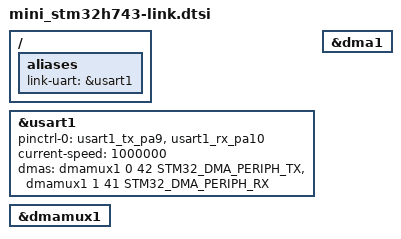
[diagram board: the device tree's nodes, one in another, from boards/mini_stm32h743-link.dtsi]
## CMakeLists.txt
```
cmake_minimum_required(VERSION 3.20.0)

# Which end of the wire this build is:
#   -DLINK_ROLE=initiator   the F767, which measures
#   -DLINK_ROLE=responder   the H743, which echoes
set(LINK_ROLE "initiator" CACHE STRING "initiator or responder")

# Link speed, in baud. Both ends must match. 1/2/3/4/6 Mbaud are exact on both
# boards; above 6 needs 8x oversampling and will not survive jumper wires.
set(LINK_BAUD "1000000" CACHE STRING "link UART baud rate")

# Which application this is:
#   -DLINK_MODE=dma      stage E3 - DMA both ways, interrupts enabled (default)
#   -DLINK_MODE=polled   stage E2 - the polled probe, kept runnable
#
# E2 is not dead code. Its numbers are what E3 is measured against, and a
# comparison made on the same boards on the same day is worth more than one
# made against a README. It is also the only build here that still proves the
# wire itself, with nothing between it and the peripheral.
set(LINK_MODE "dma" CACHE STRING "dma (E3) or polled (E2)")

if(BOARD STREQUAL "nucleo_f767zi")
  set(LINK_UART "usart6")
elseif(BOARD STREQUAL "mini_stm32h743")
  set(LINK_UART "usart1")
else()
  message(FATAL_ERROR "link: no link UART known for board '${BOARD}'")
endif()

configure_file(link-baud.overlay.in ${CMAKE_CURRENT_BINARY_DIR}/link-baud.overlay @ONLY)
list(APPEND EXTRA_DTC_OVERLAY_FILE ${CMAKE_CURRENT_BINARY_DIR}/link-baud.overlay)

find_package(Zephyr REQUIRED HINTS $ENV{ZEPHYR_BASE})
project(ctrl_lab_link)

if(LINK_ROLE STREQUAL "initiator")
  target_compile_definitions(app PRIVATE LINK_INITIATOR=1)
elseif(LINK_ROLE STREQUAL "responder")
  target_compile_definitions(app PRIVATE LINK_RESPONDER=1)
else()
  message(FATAL_ERROR "link: LINK_ROLE must be initiator or responder")
endif()

message(STATUS "link: ${BOARD} as ${LINK_ROLE}, ${LINK_UART} at ${LINK_BAUD} baud, mode ${LINK_MODE}")

target_include_directories(app PRIVATE src ../ctrl/src)

if(LINK_MODE STREQUAL "dma")
  target_sources(app PRIVATE src/e3_link.c src/link_dma.c src/link_frame.c
                             src/link_latch.c ../ctrl/src/dcp.c)
elseif(LINK_MODE STREQUAL "polled")
  target_sources(app PRIVATE src/main.c ../ctrl/src/dcp.c ../ctrl/src/trace.c)
else()
  message(FATAL_ERROR "link: LINK_MODE must be dma or polled")
endif()

# Same reason as firmware/ctrl: never let the compiler contract a*b+c into an
# FMA. Nothing here is float-heavy, but the CRC and framing code is shared with
# the control core and the two must stay byte-identical.
target_compile_options(app PRIVATE -ffp-contract=off -fno-fast-math)
```

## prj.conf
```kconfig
# The link receives by DMA, not by polling.
#
# E2 measured the polled path to its limit. uart_poll_in has to be called again
# before the next byte lands - 1.7 us at 6 Mbaud - and the 10 kHz kernel tick
# ISR is longer than that, so the poll loop lost one to three bytes per frame,
# sporadically. irq_lock() around the whole frame made it deterministic, and
# that is precisely what E3 cannot do: a control loop cannot go deaf for 40 ms,
# and locking interrupts would suppress the jitter this stage exists to
# measure. See bead ctrl-lab-b7r.7 for the decision and the alternatives.
#
# The async API moves the deadline off the CPU entirely: the DMA controller
# writes bytes into RAM on its own and the driver only wakes at buffer
# boundaries, so a late thread costs latency instead of data.
CONFIG_SERIAL=y
CONFIG_UART_ASYNC_API=y

# UART_ASYNC_API already selects DMA (drivers/serial/Kconfig.stm32:18), but the
# DMA controllers still have to be enabled per board in the overlays. Stating
# it here as well means a build that somehow loses an overlay fails on a
# missing controller rather than quietly falling back to something slower.
CONFIG_DMA=y

# The DMA ring must not be cached. Both parts are Cortex-M7 with D-cache on by
# default, and the STM32 async UART driver does no cache maintenance of its
# own - upstream's own async_api sample works around this by setting
# CONFIG_DCACHE=n on both nucleo_f746zg and nucleo_h753zi.
#
# Switching the cache off is the wrong trade here: firmware/ctrl/README.md
# measured what it buys on the H743, and E3 wants that. So instead the ring
# goes in the MPU-backed nocache section and the rest of RAM stays cacheable.
CONFIG_ARM_MPU=y
CONFIG_NOCACHE_MEMORY=y

# Cycle-accurate timing, same DWT-backed API the control runtime uses.
CONFIG_TIMING_FUNCTIONS=y

CONFIG_MAIN_STACK_SIZE=4096
```

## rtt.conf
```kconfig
# Console over RTT, for the H743 responder. Identical to firmware/ctrl/rtt.conf
# and for the same three reasons; see firmware/BRINGUP.md.
CONFIG_USE_SEGGER_RTT=y
CONFIG_RTT_CONSOLE=y
CONFIG_UART_CONSOLE=n
CONFIG_SEGGER_RTT_SECTION_DTCM=y
CONFIG_SEGGER_RTT_BUFFER_SIZE_UP=8192
```

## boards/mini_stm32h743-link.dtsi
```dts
/*
 * The link end of the H743, shared by every application that talks over it.
 * See the F767 companion for why this is included rather than duplicated.
 */

/*
 * The link end of the H743: usart1 on PA9/PA10, which the board leaves free.
 *
 *   PA9  = USART1_TX  ->  F767 D0 (PG9, RX)
 *   PA10 = USART1_RX  <-  F767 D1 (PG14, TX)
 *   GND <-> GND
 *
 * usart1 is on APB2 at 120 MHz, the fastest peripheral bus here. PB6/PB7 would
 * also carry usart1 but PB6 is QuadSPI NCS for the onboard NOR flash; PB14/PB15
 * are the clean alternative if PA9 ever turns out to be tied to USB VBUS on a
 * given board revision.
 *
 * gcd(108, 120) = 12, so 1/2/3/4/6 Mbaud are exact on both ends with zero baud
 * error. See firmware/link/README.md.
 */

/ {
	aliases {
		link-uart = &usart1;
	};

};

&usart1 {
	pinctrl-0 = <&usart1_tx_pa9 &usart1_rx_pa10>;
	pinctrl-names = "default";
	current-speed = <1000000>;
	status = "okay";

	/*
	 * DMA for the link. The H7 routes requests through DMAMUX rather than
	 * hardwiring them to streams, so the numbers mean something different
	 * than on the F767: the first cell is a DMAMUX channel (free choice)
	 * and the second is the request line ID (fixed by the peripheral).
	 * RM0433 table 121: usart1_rx_dma is 41 and usart1_tx_dma is 42.
	 *
	 * DMAMUX1 channels 0-7 are DMA1 streams 0-7 and 8-15 are DMA2's, so
	 * channels 0 and 1 put both directions on DMA1 and leave DMA2 off.
	 */
	dmas = <&dmamux1 0 42 STM32_DMA_PERIPH_TX>,
	       <&dmamux1 1 41 STM32_DMA_PERIPH_RX>;
	dma-names = "tx", "rx";
};

/*
 * DMA1 only: nothing else here needs a stream, and dmamux_stm32 resolves the
 * channel-to-controller table at build time, so a disabled DMA2 costs nothing
 * beyond the channels that would have mapped to it.
 *
 * The ring these streams write into must stay out of DTCM. DMA1 lives in the
 * D2 domain and cannot reach the D1 core-coupled memories at all; sram0 on
 * this board is AXI SRAM at 0x24000000, which it reaches through the D2-to-D1
 * bus matrix. That is the opposite of the rule for the control pools in
 * firmware/BRINGUP.md, and the reason link buffers must not follow them into
 * dtcm.
 */
&dma1 {
	status = "okay";
};

&dmamux1 {
	status = "okay";
};
```

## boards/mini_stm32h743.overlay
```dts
/* The link probe's own overlay. The link itself is in the shared .dtsi, which
 * firmware/ctrl includes too; the DTCM selection stays here because it is a
 * per-application choice.
 */

#include "mini_stm32h743-link.dtsi"

/ {
	chosen {
		/* Same reason as every other application here: the board .dts
		 * declares dtcm but never selects it, so without this the
		 * __dtcm_* sections do not exist. See firmware/BRINGUP.md.
		 */
		zephyr,dtcm = &dtcm;
	};
};
```

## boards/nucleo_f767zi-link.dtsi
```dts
/*
 * The link end of the F767, shared by every application that talks over it.
 *
 * Included rather than duplicated: firmware/ctrl needs exactly these nodes to
 * bind an Input or Output block to the link, and a second copy of the DMA
 * stream numbers is a second place to get them wrong. The DTCM selection in
 * each app's own overlay stays duplicated, because that is one line of settled
 * board fact; this is not.
 */

/*
 * The link end of the F767: usart6, which is the Arduino header's serial.
 *
 *   D1 = PG14 = USART6_TX  ->  H743 PA10 (RX)
 *   D0 = PG9  = USART6_RX  <-  H743 PA9  (TX)
 *   GND <-> GND
 *
 * usart6 is on APB2 at 108 MHz, twice the clock of the APB1 UARTs, which is why
 * it is the link rather than a spare usart2. It is already enabled in the board
 * .dts at 115200; the generated link-baud.overlay overrides the speed.
 *
 * The console stays on usart3 (ST-Link VCP), so measurements print over a
 * channel that is not the one being measured.
 */

/ {
	aliases {
		link-uart = &usart6;
	};
};

/*
 * DMA for the link UART. RM0410 table 28: DMA2 channel 5 carries USART6_TX on
 * streams 6 and 7, and USART6_RX on streams 1 and 2. Nothing else in this
 * application uses DMA2, so the first of each pair is free.
 *
 * The fourth cell is the FIFO threshold. It is inert here - dma_stm32 only
 * turns the stream FIFO on when a burst is configured (stm32_dma_configure ->
 * stm32_dma_check_fifo_mburst) and the async UART driver transfers single
 * bytes, so the stream runs in direct mode. It is spelled out anyway because
 * the binding requires four cells and because this is what upstream's own
 * async_api sample passes on the F7.
 */
&usart6 {
	dmas = <&dma2 6 5 STM32_DMA_PERIPH_TX STM32_DMA_FIFO_FULL>,
	       <&dma2 1 5 STM32_DMA_PERIPH_RX STM32_DMA_FIFO_FULL>;
	dma-names = "tx", "rx";
};

&dma2 {
	status = "okay";
};
```

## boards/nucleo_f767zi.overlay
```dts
/* The link probe's own overlay. The link itself is in the shared .dtsi, which
 * firmware/ctrl includes too.
 */

#include "nucleo_f767zi-link.dtsi"
```

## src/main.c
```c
/*
 * ctrl-lab link probe - stage E2.
 *
 * Moves bytes between the two boards and finds out what they cost. No control
 * loop, no plan execution: the only unknown this stage adds is the transport,
 * and mixing it with anything else would make a bad number unattributable.
 *
 *   F767 (initiator)  D1 = PG14 = usart6 TX  ->  PA10 = usart1 RX  (H743)
 *                     D0 = PG9  = usart6 RX  <-  PA9  = usart1 TX
 *                     GND <-> GND
 *
 * Both link UARTs are on APB2 - 108 MHz on the F767, 120 MHz on the H743 -
 * which is the fastest peripheral clock on each part.
 *
 * Two measurements:
 *
 *   ping   one byte out, one byte back, timed on the initiator's clock. This is
 *          the only way to get an accurate delay across two boards that have no
 *          shared timebase: measure the round trip on one clock, and have the
 *          far side report its own turnaround so it can be subtracted.
 *
 *   frame  a real DCPT frame, verified on the far side with the same CRC code
 *          the control runtime uses. Answers whether the link is trustworthy
 *          for stage E3, and what it costs in throughput.
 *
 * What `ping` does NOT measure: uart_poll_out returns once the byte is handed
 * to the transmit register, not once it has left the wire. The last character
 * time is therefore outside the measurement on each hop. At 1 Mbaud that is
 * 10 us per direction, which is large - so the reported delay is a lower bound
 * on the wire time and an accurate measure of software-to-software latency.
 */

#include <zephyr/kernel.h>
#include <zephyr/device.h>
#include <zephyr/drivers/uart.h>
#include <zephyr/sys/printk.h>
#include <string.h>
#include <zephyr/timing/timing.h>

#include "dcp.h"
#include "trace.h"

#define LINK_NODE DT_ALIAS(link_uart)
#if !DT_NODE_EXISTS(LINK_NODE)
#error "no link-uart alias - add one in boards/<board>.overlay"
#endif

static const struct device *const link = DEVICE_DT_GET(LINK_NODE);

/* Protocol, deliberately one byte wide. Anything richer would need framing of
 * its own, and the DCPT frame already brings framing for the payload.
 */
#define CMD_PING  'P'
#define RSP_PING  'p'
#define CMD_FRAME 'F'
#define CMD_REPORT 'R'
#define RSP_CRC_OK   'Y'
#define RSP_CRC_BAD  'N'

#define PING_COUNT 1000

/* A synthetic trace frame: 200 rows of 4 signals. Big enough that throughput
 * means something, small enough to sit in RAM on both boards.
 */
#define FRAME_ROWS    200
#define FRAME_SIGNALS 4
#define FRAME_BYTES (CTRL_TRACE_HEADER_LEN + \
		     FRAME_ROWS * (1 + FRAME_SIGNALS) * 4 + CTRL_TRACE_TRAILER_LEN)

static uint8_t frame[FRAME_BYTES];

/* Blocking single-byte read. Returns false if nothing arrived within the
 * timeout, which is what distinguishes "the far side is not there" from "the
 * far side is slow".
 */
/* Bulk receive with an absolute deadline.
 *
 * The fast path does NO timing work at all: while bytes keep arriving,
 * uart_poll_in succeeds and nothing else is called. The deadline is only
 * consulted when a poll comes back empty, which is the only time the answer can
 * have changed.
 *
 * That matters more than it looks. The first version called link_get() once per
 * byte, and each call read sys_clock_hw_cycles_per_sec() and k_cycle_get_32()
 * to build a fresh deadline. At 1 Mbaud a byte lands every 10 us and that fits;
 * at 2 Mbaud the budget halves to 5 us and it does not, so the receiver fell
 * behind a blast it could easily keep up with and every frame above 1 Mbaud
 * failed CRC while single-byte pings at 6 Mbaud were flawless. Measured.
 */
#ifdef LINK_RESPONDER
static uint32_t cycles_per_ms;

/* Bulk receive that does NO timing work until a byte is actually late.
 *
 * Every boundary in this protocol turned out to be a place where a few hundred
 * cycles of bookkeeping loses a byte, because the STM32 receive register holds
 * exactly one and the sender never pauses. It cost four rounds to learn:
 *
 *   - a bitwise CRC between payload and trailer lost 11 of 12 trailer bytes
 *   - a 24-byte header CRC before the payload lost 1
 *   - and building a deadline (which called sys_clock_hw_cycles_per_sec) after
 *     reading the 'F' command lost the first header byte, which shifted the
 *     whole frame by one and showed up as "header 32/32 (crc bad),
 *     trailer 11/12"
 *
 * So the deadline is armed lazily: nothing is computed while bytes are
 * arriving, and the clock is only read once a poll comes back empty. The fast
 * path is uart_poll_in and nothing else.
 */
static uint32_t link_recv(uint8_t *out, uint32_t len, uint32_t timeout_ms)
{
	uint32_t got = 0;
	uint32_t deadline = 0;
	bool armed = false;

	while (got < len) {
		if (uart_poll_in(link, &out[got]) == 0) {
			got++;
			armed = false;
			continue;
		}
		if (!armed) {
			deadline = k_cycle_get_32() + timeout_ms * cycles_per_ms;
			armed = true;
			continue;
		}
		if ((int32_t)(k_cycle_get_32() - deadline) >= 0) {
			break;
		}
	}
	return got;
}
#endif /* LINK_RESPONDER */

#ifdef LINK_INITIATOR
static bool link_get(uint8_t *out, uint32_t timeout_us)
{
	/* Spin tightly. The first version slept k_busy_wait(1) between polls,
	 * which reads the cycle counter and costs far more than the 1 us it
	 * claims - at 1 Mbaud a byte lands every 10 us and the STM32 USART
	 * receive register holds exactly one, so a slow poll loop overruns it and
	 * drops bytes. That showed up as a frame CRC mismatch and a transfer
	 * running 5x slower than the wire, because every dropped byte then cost a
	 * full receive timeout. Measured, not theorised: 4044 bytes took 210 ms
	 * against a 40 ms floor.
	 *
	 * The deadline is compared as a signed difference so the 32-bit cycle
	 * counter wrapping mid-wait is harmless.
	 */
	const uint32_t per_us = sys_clock_hw_cycles_per_sec() / 1000000U;
	const uint32_t deadline = k_cycle_get_32() + timeout_us * per_us;

	do {
		if (uart_poll_in(link, out) == 0) {
			return true;
		}
	} while ((int32_t)(k_cycle_get_32() - deadline) < 0);

	return false;
}
#endif /* LINK_INITIATOR */

#ifdef LINK_INITIATOR
static void link_put(const uint8_t *bytes, uint32_t len)
{
	for (uint32_t i = 0; i < len; i++) {
		uart_poll_out(link, bytes[i]);
	}
}
#endif

/* --- frame construction, initiator only ---------------------------------- */

#ifdef LINK_INITIATOR
static uint32_t frame_len;

static void frame_sink(void *ctx, const uint8_t *bytes, uint32_t len)
{
	ARG_UNUSED(ctx);

	for (uint32_t i = 0; i < len && frame_len < sizeof(frame); i++) {
		frame[frame_len++] = bytes[i];
	}
}

/* Deterministic contents, so both ends can build the identical frame and any
 * disagreement is the wire rather than the data.
 */
static void build_frame(void)
{
	struct ctrl_trace_writer writer;
	float row[FRAME_SIGNALS];

	frame_len = 0;
	ctrl_trace_begin(&writer, frame_sink, NULL, 0x1234567890abcdefULL,
			 FRAME_SIGNALS, FRAME_ROWS);

	for (uint32_t k = 0; k < FRAME_ROWS; k++) {
		for (int s = 0; s < FRAME_SIGNALS; s++) {
			row[s] = (float)(k * FRAME_SIGNALS + s);
		}
		ctrl_trace_row(&writer, (float)k * 0.001f, row);
	}
	ctrl_trace_end(&writer);
}
#endif /* LINK_INITIATOR */

#ifdef LINK_RESPONDER

/* The H743 end. Never returns: it has to keep answering, and on this part
 * letting Zephyr idle into WFI also takes the core off the SWD debug bus, which
 * is how RTT is read. See firmware/BRINGUP.md.
 */
int main(void)
{
	printk("\nctrl-lab link responder\n");
	printk("board " CONFIG_BOARD_TARGET ", link %s\n", link->name);

	if (!device_is_ready(link)) {
		printk("FAIL: link uart not ready\n");
		return 0;
	}

	timing_init();
	timing_start();

	/* Hoisted: reading this per call was itself enough to drop a byte. */
	cycles_per_ms = sys_clock_hw_cycles_per_sec() / 1000U;

	uint32_t pings = 0, frames = 0, bad = 0, last_payload = 0;

	/* Where the last frame got to. Reported verbatim so a stall is located
	 * rather than inferred: which phase, and how many bytes of what it
	 * expected actually arrived.
	 */
	const char *phase = "none";
	uint32_t hdr_got = 0, pay_got = 0, trl_got = 0, stray = 0;
	bool hdr_crc_ok = false;
	uint32_t turn_best = UINT32_MAX, turn_worst = 0;
	uint64_t turn_total = 0;

	printk("listening\n");

	while (1) {
		uint8_t cmd;

		if (uart_poll_in(link, &cmd) != 0) {
			continue;
		}

		if (cmd != CMD_PING && cmd != CMD_FRAME && cmd != CMD_REPORT) {
			stray++;
			continue;
		}

		if (cmd == CMD_PING) {
			timing_t t0 = timing_counter_get();

			uart_poll_out(link, RSP_PING);

			timing_t t1 = timing_counter_get();
			uint32_t turn = (uint32_t)timing_cycles_get(&t0, &t1);

			turn_best = MIN(turn_best, turn);
			turn_worst = MAX(turn_worst, turn);
			turn_total += turn;
			pings++;

			/* Deliberately silent here. printk between the ping phase
			 * and the frame is enough to miss the first bytes of the
			 * frame: the STM32 USART holds one received byte and the
			 * initiator starts sending immediately. That cost a full
			 * baud sweep of CRC mismatches at every rate, including one
			 * that had passed minutes earlier. Stats are printed after
			 * the frame instead, when the link is quiet.
			 */
		} else if (cmd == CMD_FRAME) {
			/* Header first, because payload_len lives in it and must
			 * be CRC-checked before it is trusted as a length.
			 */
			uint8_t header[CTRL_TRACE_HEADER_LEN];

			/* 200 ms, deliberately SHORTER than the initiator's wait
			 * for our verdict.
			 *
			 * This is the bug that outlasted four fixes. The responder
			 * used to wait 2000 ms for missing bytes while the
			 * initiator gave up after 500 ms - so a single lost byte
			 * desynchronised them permanently: the initiator moved on
			 * and started the next phase while this side was still
			 * blocked, and every subsequent run inherited the mess.
			 * Whoever waits longer must be the one asking.
			 */
			/* Resynchronise on the magic instead of trusting stream
			 * position.
			 *
			 * The frame carries "DCPT" precisely so a reader can find it
			 * in a stream it does not otherwise understand, and not using
			 * that made every failure self-perpetuating: a frame that
			 * ended one byte short left a byte behind, the next run read
			 * it as the start of its header, and the shift repeated for
			 * ever. Failures went from intermittent to permanent and it
			 * looked like a rate problem.
			 *
			 * Scanning costs nothing in the good case - the magic is the
			 * first four bytes - and it makes a bad frame cost exactly
			 * one frame instead of every frame after it.
			 */
			/* Interrupts off for the whole frame.
			 *
			 * The instrumentation narrowed the loss to mid-stream and
			 * sporadic - trailer short by one to three bytes, varying
			 * run to run - which a tight poll loop cannot cause on its
			 * own at 10 us per byte. What can is the 10 kHz kernel tick
			 * preempting it: the H743's ISR path is both expensive and
			 * variable, which the E1 jitter work already measured
			 * (5183 ns of tick jitter, and awake-time outliers).
			 *
			 * A ~40 ms lock is not something a control loop could do, but
			 * this is a transport probe with nothing else to be late for,
			 * and it isolates the cause. If it is the tick, the real fix
			 * for stage E is DMA or the H7's USART FIFO, not a lock.
			 */
			const unsigned int key = irq_lock();

			phase = "sync";
			hdr_got = 0;
			{
				uint8_t window[4] = { 0, 0, 0, 0 };
				uint32_t scanned = 0;

				while (scanned < sizeof(frame)) {
					uint8_t b;

					if (link_recv(&b, 1, 200) != 1) {
						break;
					}
					scanned++;
					window[0] = window[1];
					window[1] = window[2];
					window[2] = window[3];
					window[3] = b;
					if (window[0] == 'D' && window[1] == 'C' &&
					    window[2] == 'P' && window[3] == 'T') {
						break;
					}
				}
				if (window[0] == 'D' && window[3] == 'T') {
					memcpy(header, window, 4);
					hdr_got = 4 + link_recv(&header[4],
							        sizeof(header) - 4, 200);
				}
			}
			phase = "header";
			pay_got = 0;
			trl_got = 0;
			hdr_crc_ok = false;

			bool ok = (hdr_got == sizeof(header));
			uint32_t payload_len = 0;
			uint32_t want_hdr_crc = 0;

			if (ok) {
				/* Shifts only. The header CRC is deliberately NOT
				 * checked here: it is 24 bytes of bitwise CRC, ~192
				 * iterations, and at 1 Mbaud that is most of a byte
				 * time - long enough to miss the first payload byte
				 * while the stream keeps coming. The instrumentation
				 * caught it as "trailer 11/12", one byte short.
				 *
				 * payload_len is still bounds-checked before it is
				 * used as a length, which is the check that matters
				 * for safety; the CRC then confirms it afterwards,
				 * when nothing is in flight.
				 */
				for (int i = 0; i < 4; i++) {
					payload_len |= (uint32_t)header[20 + i] << (8 * i);
					want_hdr_crc |= (uint32_t)header[24 + i] << (8 * i);
				}
				ok = (payload_len + CTRL_TRACE_HEADER_LEN +
				      CTRL_TRACE_TRAILER_LEN <= sizeof(frame));
			}

			/* Buffer the payload, then CRC it.
			 *
			 * Keeping the CRC out of the receive loop is the right
			 * shape - at 6 Mbaud a byte lands every 1.67 us, about 400
			 * cycles, and uart_poll_in plus a bitwise 8-iteration CRC
			 * does not fit in that. But see the bead: bulk transfer is
			 * only verified at 1 Mbaud, and the higher rates fail for a
			 * reason not yet found.
			 */
			/* Payload AND trailer in one receive, then CRC.
			 *
			 * They are one continuous stream and must be read as one.
			 * Computing the CRC between them is what broke this: a
			 * bitwise CRC over 4000 bytes is ~32000 loop iterations,
			 * and at 1 Mbaud the 12 trailer bytes arrive during that
			 * gap and land in a one-byte register that is not being
			 * read. The instrumentation said it exactly - "payload
			 * 4000/4000, trailer 1/12" - eleven bytes lost, which is
			 * the whole trailer bar the one still sitting in the
			 * register.
			 *
			 * The lesson generalises past this bug: on a polled link
			 * there is no such thing as a safe pause between two parts
			 * of the same transfer. Receive everything, then think.
			 */
			const uint32_t tail = payload_len + CTRL_TRACE_TRAILER_LEN;
			uint32_t crc = CTRL_CRC32_INIT;
			const uint8_t *trailer = &frame[payload_len];

			if (ok) {
				phase = "payload+trailer";
				pay_got = link_recv(frame, tail, 200);
				ok = (pay_got == tail);
				trl_got = pay_got > payload_len ? pay_got - payload_len : 0;
				pay_got = MIN(pay_got, payload_len);
			}

			if (ok) {
				/* Everything is received; now it is safe to compute. */
				hdr_crc_ok = (ctrl_crc32(header, 24) == want_hdr_crc);
				crc = ctrl_crc32_update(crc, frame, payload_len);
				ok = hdr_crc_ok;
			}

			uint32_t want_crc = 0;

			if (ok) {
				for (int i = 0; i < 4; i++) {
					want_crc |= (uint32_t)trailer[i] << (8 * i);
				}
				ok = (CTRL_CRC32_FINAL(crc) == want_crc);
			}

			frames++;
			if (!ok) {
				bad++;
			}
			irq_unlock(key);

			if (ok) {
				phase = "complete";
			}
			uart_poll_out(link, ok ? RSP_CRC_OK : RSP_CRC_BAD);
			last_payload = payload_len;

			/* No drain here. An earlier version swallowed leftovers after
			 * every frame and swallowed the initiator's CMD_REPORT with
			 * them, so the far side went silent and the diagnostic that
			 * exists to explain failures stopped being emitted. The magic
			 * resync above already recovers from a desynchronised stream,
			 * which is the job a drain was trying to do.
			 */
		} else if (cmd == CMD_REPORT) {
			/* The ONLY place this side prints.
			 *
			 * Printing anywhere else loses bytes, and it took three
			 * sweeps to accept that. The console is not the link, but
			 * printk still takes time, and the receive register holds
			 * exactly one byte - so any print that overlaps an incoming
			 * transfer drops data. It bit twice: once between the ping
			 * phase and the frame, and again between two initiator runs,
			 * because console.py resets the board and the initiator
			 * therefore runs once on flash and once on reset.
			 *
			 * Now the initiator asks for the report after it already has
			 * its verdict, so the link is provably idle.
			 */
			printk("frames %u (bad %u), last payload %u bytes\n", frames, bad,
			       last_payload);
			printk("last frame reached '%s': header %u/%u (crc %s), "
			       "payload %u/%u, trailer %u/%u\n",
			       phase, hdr_got, (uint32_t)CTRL_TRACE_HEADER_LEN,
			       hdr_crc_ok ? "ok" : "bad", pay_got, last_payload, trl_got,
			       (uint32_t)CTRL_TRACE_TRAILER_LEN);
			printk("stray bytes (not P/F/R): %u\n", stray);
			printk("pings %u, turnaround min=%u mean=%u max=%u cycles\n", pings,
			       pings ? turn_best : 0,
			       pings ? (uint32_t)(turn_total / pings) : 0, turn_worst);
		}
	}
	return 0;
}

#else /* LINK_INITIATOR */

int main(void)
{
	printk("\nctrl-lab link initiator\n");
	printk("board " CONFIG_BOARD_TARGET ", link %s\n", link->name);
	printk("core %u Hz\n", sys_clock_hw_cycles_per_sec());

	if (!device_is_ready(link)) {
		printk("FAIL: link uart not ready\n");
		return 0;
	}

	timing_init();
	timing_start();

	/* Drain anything the responder left in flight from a previous run, so the
	 * first ping is not answered by a stale byte.
	 */
	uint8_t junk;

	while (uart_poll_in(link, &junk) == 0) {
	}

	/* --- ping round trip --- */
	uint32_t best = UINT32_MAX, worst = 0, lost = 0;
	uint64_t total = 0;
	uint32_t counted = 0;

	for (uint32_t i = 0; i < PING_COUNT; i++) {
		uint8_t reply;

		timing_t t0 = timing_counter_get();

		uart_poll_out(link, CMD_PING);

		if (!link_get(&reply, 50000) || reply != RSP_PING) {
			lost++;
			continue;
		}

		timing_t t1 = timing_counter_get();
		uint32_t rtt = (uint32_t)timing_cycles_get(&t0, &t1);

		best = MIN(best, rtt);
		worst = MAX(worst, rtt);
		total += rtt;
		counted++;
	}

	const uint32_t hz = sys_clock_hw_cycles_per_sec();

	if (counted == 0) {
		printk("FAIL: no replies. Check TX/RX are crossed, GND is shared,\n");
		printk("      and that both ends are built with the same LINK_BAUD.\n");
		return 0;
	}

	const uint32_t mean = (uint32_t)(total / counted);

	printk("\nping        %u of %u answered, %u lost\n", counted, PING_COUNT, lost);
	printk("rtt_cycles  min=%u mean=%u max=%u spread=%u\n", best, mean, worst,
	       worst - best);
	printk("rtt_ns      min=%u mean=%u max=%u\n",
	       (uint32_t)((uint64_t)best * 1000000000U / hz),
	       (uint32_t)((uint64_t)mean * 1000000000U / hz),
	       (uint32_t)((uint64_t)worst * 1000000000U / hz));
	printk("one_way_ns  ~%u (half the round trip, before subtracting the\n",
	       (uint32_t)((uint64_t)mean * 1000000000U / hz / 2U));
	printk("            responder turnaround it reports on its own console)\n");

	/* --- bulk frame --- */

	/* Let the responder finish whatever the ping phase left it doing. The
	 * frame arrives as one uninterrupted blast and the far side has a
	 * one-byte receive register, so it must be idle and listening first.
	 */
	k_msleep(50);

	build_frame();
	printk("\nframe       %u bytes, %u rows x %u signals\n", frame_len, FRAME_ROWS,
	       FRAME_SIGNALS);

	timing_t f0 = timing_counter_get();

	uart_poll_out(link, CMD_FRAME);
	link_put(frame, frame_len);

	uint8_t verdict = 0;
	/* 500 ms, comfortably longer than the responder's 200 ms deadline, so it
	 * always answers before we give up on it.
	 */
	bool answered = link_get(&verdict, 500000);
	timing_t f1 = timing_counter_get();

	if (!answered) {
		/* Ask anyway. A frame that never gets a verdict is exactly the
		 * case where the far side's account of where it stalled is worth
		 * having, and returning here is what hid it for three sweeps.
		 */
		printk("FAIL: responder never answered the frame\n");
		k_msleep(300);
		uart_poll_out(link, CMD_REPORT);
		k_msleep(100);
		printk("(asked the responder to report; read it on its console)\n");
		return 0;
	}

	const uint32_t cycles = (uint32_t)timing_cycles_get(&f0, &f1);
	const uint32_t us = (uint32_t)((uint64_t)cycles * 1000000U / hz);

	printk("frame_crc   %s\n", verdict == RSP_CRC_OK ? "OK on the far side"
							: "*** MISMATCH ***");
	printk("frame_time  %u cycles, %u us\n", cycles, us);
	printk("throughput  %u KB/s (includes the far side's CRC pass)\n",
	       us ? (uint32_t)((uint64_t)frame_len * 1000U / us) : 0U);

	/* Ask the far side to report now, when nothing is in flight. */
	uart_poll_out(link, CMD_REPORT);

	printk("\ndone\n");
	return 0;
}

#endif
```

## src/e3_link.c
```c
/*
 * ctrl-lab link validation - stage E3.
 *
 * E2 established that the wire and the framing are sound, and that a polled
 * receive only survives the 10 kHz kernel tick if interrupts are locked for
 * the whole frame. This is the same link with the receive path replaced: DMA
 * in both directions, interrupts enabled throughout, and the tick running.
 *
 * It answers one question - does the transport still lose nothing when nothing
 * is protecting it - and reports the numbers stage E3 needs on top:
 *
 *   loss        every packet is counted at both ends and CRC-checked on
 *               arrival. Zero bad frames and no resyncs after the handshake is
 *               the pass condition.
 *   latency     round trip measured on the initiator's clock, with the wire
 *               time and the responder's own turnaround subtracted, which is
 *               what makes it comparable to E2's ping figure.
 *   skew        the two crystals differenced through the packets themselves.
 *               Nothing here shares a timebase, so this is the only way to see
 *               it - see link_latch.c.
 *
 * Both ends run the SAME loop shape as a control step would: take whatever the
 * latch holds, act, move on. Nothing blocks, nothing spins on the UART, and
 * there is no irq_lock() anywhere in this file. That is the point.
 */

#include <zephyr/kernel.h>
#include <zephyr/device.h>
#include <zephyr/drivers/uart.h>
#include <zephyr/sys/printk.h>
#include <zephyr/timing/timing.h>
#include <string.h>

#include "link_dma.h"
#include "link_frame.h"
#include "link_latch.h"
#include "link_pkt.h"

#define LINK_NODE DT_ALIAS(link_uart)
#if !DT_NODE_EXISTS(LINK_NODE)
#error "no link-uart alias - add one in boards/<board>.overlay"
#endif

static const struct device *const link = DEVICE_DT_GET(LINK_NODE);

/* Taken from the devicetree rather than the CMake variable, so it is the baud
 * the UART was actually configured with and not the one that was requested.
 */
#define LINK_BAUD DT_PROP(LINK_NODE, current_speed)

/* 8N1, so ten bits per byte on the wire. */
#define PKT_WIRE_NS ((uint32_t)(((uint64_t)CTRL_LINK_PKT_LEN * 10ULL * 1000000000ULL) \
			        / (uint64_t)LINK_BAUD))

#define BURST_PACKETS   10000U
#define PKT_TIMEOUT_US  5000U	/* per packet; ~45x the round trip at 6 Mbaud */
#define MAX_CONSEC_DROP 50U	/* abort rather than grind through a dead link */

/* Handshake sequence numbers, kept far away from the burst's 1..10000 so a
 * late handshake echo can never be mistaken for a burst packet.
 */
#define HANDSHAKE_SEQ_BASE 0xf0000000U
#define HANDSHAKE_TRIES    100U

static uint32_t cycles_per_us;

#ifdef LINK_INITIATOR
/* Waits for the latch to hold a packet with this exact seq.
 *
 * A spin, deliberately, and a bounded one - but note what it is NOT doing: it
 * never touches the UART, never disables anything, and the DMA keeps filling
 * the ring the whole time it runs. A late thread here costs latency and not
 * data, which is the entire difference between this stage and E2.
 */
static bool wait_for_seq(uint32_t want, struct ctrl_link_pkt *out, uint32_t *rx_cycle,
			 uint32_t timeout_us)
{
	const uint32_t deadline = k_cycle_get_32() + timeout_us * cycles_per_us;

	do {
		if (link_dma_get_latest(out, rx_cycle) && out->seq == want) {
			return true;
		}
	} while ((int32_t)(k_cycle_get_32() - deadline) < 0);

	return false;
}
#endif /* LINK_INITIATOR */

#ifdef LINK_INITIATOR
/* What the instruments cost, before any of it is blamed on the link.
 *
 * The first decomposed run put 25.5 us into handing a packet to the transmit
 * DMA and 25.7 us into noticing one had arrived - two operations with almost
 * nothing in common, agreeing to three digits. Numbers that similar are rarely
 * about the thing being measured, so this measures the measuring: the DWT
 * counter, read through the timing API, timing the SysTick-backed clock the
 * link path actually calls.
 */
static void measure_instrument_cost(void)
{
	const unsigned int reps = 1000;
	struct ctrl_link_pkt scratch;
	uint32_t scratch_cycle;
	timing_t a, b;

	timing_init();
	timing_start();

	a = timing_counter_get();
	for (unsigned int i = 0; i < reps; i++) {
		(void)k_cycle_get_32();
	}
	b = timing_counter_get();
	printk("cost        k_cycle_get_32 %u cycles\n",
	       (uint32_t)(timing_cycles_get(&a, &b) / reps));

	a = timing_counter_get();
	for (unsigned int i = 0; i < reps; i++) {
		(void)link_dma_get_latest(&scratch, &scratch_cycle);
	}
	b = timing_counter_get();
	printk("cost        link_dma_get_latest %u cycles\n",
	       (uint32_t)(timing_cycles_get(&a, &b) / reps));

	a = timing_counter_get();
	for (unsigned int i = 0; i < reps; i++) {
		(void)sys_clock_tick_get();
	}
	b = timing_counter_get();
	printk("cost        sys_clock_tick_get %u cycles\n",
	       (uint32_t)(timing_cycles_get(&a, &b) / reps));

	/* The CPU half of link_dma_send: the copy into the nocache staging
	 * buffer and the CRC over it. Whatever the send costs beyond this is
	 * the driver arming the transmit DMA, and that subtraction is the
	 * whole point of measuring it.
	 */
	memset(&scratch, 0, sizeof(scratch));
	a = timing_counter_get();
	for (unsigned int i = 0; i < reps; i++) {
		link_frame_stamp(&scratch);
	}
	b = timing_counter_get();
	printk("cost        stage+crc a packet %u cycles\n",
	       (uint32_t)(timing_cycles_get(&a, &b) / reps));

	timing_stop();
}
#endif /* LINK_INITIATOR */

static void print_banner(const char *role)
{
	printk("\nctrl-lab link %s - stage E3, DMA receive\n", role);
	printk("board " CONFIG_BOARD_TARGET ", link %s at %u baud\n", link->name,
	       (unsigned int)LINK_BAUD);
	printk("core %u Hz, kernel tick %u Hz, dcache %s\n",
	       sys_clock_hw_cycles_per_sec(), CONFIG_SYS_CLOCK_TICKS_PER_SEC,
	       IS_ENABLED(CONFIG_DCACHE) ? "on" : "off");
	printk("packet %u bytes, %u ns on the wire\n", (unsigned int)CTRL_LINK_PKT_LEN,
	       PKT_WIRE_NS);
}

static void print_link_stats(const char *who)
{
	struct link_dma_stats s;

	link_dma_get_stats(&s);
	printk("%s slots=%u ok=%u bad=%u short=%u resync=%u realign=%u "
	       "uart_err=%u rearm=%u\n", who, s.rx_slots, s.rx_ok, s.rx_bad,
	       s.rx_short, s.resyncs, s.realigns, s.rx_errors, s.rx_restarts);
	printk("%s tx_done=%u tx_rejected=%u\n", who, s.tx_done, s.tx_rejected);
	printk("%s rx_callback first=%u worst=%u mean=%u cycles (after the first)\n",
	       who, s.rx_first_cycles, s.rx_worst_cycles,
	       s.rx_slots > 1U ? (uint32_t)(s.rx_total_cycles / (s.rx_slots - 1U)) : 0U);
}

#ifdef LINK_RESPONDER

/* The H743 end. Echoes every packet it validates, straight back, as fast as it
 * can - which at one DMA transmit per received packet is the same shape a
 * plant model would have: consume the newest sample, produce one output.
 *
 * Never returns. On this part letting Zephyr idle into WFI also takes the core
 * off the SWD debug bus, which is how RTT is read - see firmware/BRINGUP.md.
 */
int main(void)
{
	print_banner("responder");

	if (!link_dma_init(link)) {
		printk("FAIL: link_dma_init\n");
		return 0;
	}

	cycles_per_us = sys_clock_hw_cycles_per_sec() / 1000000U;

	struct ctrl_link_pkt pkt, reply;
	uint32_t rx_cycle;
	bool primed = false;
	uint32_t last_seq = 0;

	uint32_t echoed = 0, gaps = 0, tx_fail = 0;
	uint32_t turn_best = UINT32_MAX, turn_worst = 0;
	uint64_t turn_total = 0;
	uint32_t quiet_since = k_cycle_get_32();
	bool reported = true;

	printk("listening\n");

	while (1) {
		if (!link_dma_get_latest(&pkt, &rx_cycle) ||
		    (primed && pkt.seq == last_seq)) {
			/* Report once the stream has been quiet for a while.
			 * Deferred rather than printed as it goes: printk is
			 * slow, and although the DMA would keep receiving
			 * through it - which E2's polled loop could not - a
			 * console write in the middle of a measurement still
			 * shows up in the numbers.
			 */
			if (!reported && echoed > 0U &&
			    (uint32_t)(k_cycle_get_32() - quiet_since) >
				    200000U * cycles_per_us) {
				printk("\nechoed %u, seq gaps %u, tx refused %u\n",
				       echoed, gaps, tx_fail);
				printk("turnaround min=%u mean=%u max=%u cycles "
				       "(%u ns worst)\n", turn_best,
				       (uint32_t)(turn_total / echoed), turn_worst,
				       (uint32_t)((uint64_t)turn_worst * 1000000000ULL /
						  sys_clock_hw_cycles_per_sec()));
				print_link_stats("responder");
				reported = true;
			}
			continue;
		}

		if (primed) {
			const uint32_t delta = (uint32_t)(pkt.seq - last_seq);

			/* Only within the burst; a handshake seq sitting far
			 * away from it is not a gap of four billion packets.
			 */
			if (delta > 1U && delta < BURST_PACKETS) {
				gaps += delta - 1U;
			}
		}
		last_seq = pkt.seq;
		primed = true;

		/* Echo. The payload goes back untouched so the initiator can
		 * check the round trip end to end; tx_tick carries THIS
		 * board's kernel tick, which is what lets the far side
		 * difference the two crystals.
		 */
		reply = pkt;
		reply.tx_tick = (uint32_t)sys_clock_tick_get();
		if (!link_dma_send(&reply)) {
			tx_fail++;
		}

		const uint32_t turn = k_cycle_get_32() - rx_cycle;

		turn_best = MIN(turn_best, turn);
		turn_worst = MAX(turn_worst, turn);
		turn_total += turn;
		echoed++;

		quiet_since = k_cycle_get_32();
		reported = false;
	}
}

#else /* LINK_INITIATOR */

int main(void)
{
	print_banner("initiator");

	if (!link_dma_init(link)) {
		printk("FAIL: link_dma_init\n");
		return 0;
	}

	cycles_per_us = sys_clock_hw_cycles_per_sec() / 1000000U;

	measure_instrument_cost();

	struct ctrl_link_pkt pkt, echo;
	uint32_t rx_cycle;

	/* Let the far side finish booting and arm its DMA. Both boards are
	 * reset by their own probe and there is no ordering between them, so
	 * without this the first packets land in a receiver that is not
	 * listening yet - and with a fixed-size framing, a stream that starts
	 * mid-packet costs a resync rather than a byte.
	 */
	k_sleep(K_MSEC(200));

	/* Handshake. One packet out, the same packet back, and the burst does
	 * not start until that has happened: it proves the far side is up, the
	 * baud rates agree, and both framings are aligned before anything is
	 * being counted.
	 */
	bool up = false;

	for (uint32_t try = 0; try < HANDSHAKE_TRIES && !up; try++) {
		memset(&pkt, 0, sizeof(pkt));
		pkt.signal_count = CTRL_LINK_SIGNALS;
		pkt.seq = HANDSHAKE_SEQ_BASE + try;
		pkt.tx_tick = (uint32_t)sys_clock_tick_get();

		if (link_dma_send(&pkt)) {
			up = wait_for_seq(pkt.seq, &echo, &rx_cycle, 10000U);
		} else {
			k_sleep(K_MSEC(1));
		}
	}

	if (!up) {
		printk("\nFAIL: no answer after %u handshake attempts.\n",
		       HANDSHAKE_TRIES);
		printk("      Check TX/RX are crossed, GND is shared, and that\n");
		printk("      both ends are built with the same LINK_BAUD.\n");
		print_link_stats("initiator");
		return 0;
	}

	printk("handshake ok, sending %u packets\n", BURST_PACKETS);

	struct link_latch latch;

	link_latch_init(&latch, sys_clock_hw_cycles_per_sec() /
				CONFIG_SYS_CLOCK_TICKS_PER_SEC);

	uint32_t answered = 0, dropped = 0, consec_drop = 0, payload_bad = 0;
	uint32_t tx_refused = 0, fault = 0, overrun = 0;
	uint32_t rtt_best = UINT32_MAX, rtt_worst = 0;
	uint64_t rtt_total = 0;

	/* The round trip on its own is a number with nowhere to go. Split into
	 * the three pieces that can actually be acted on:
	 *
	 *   setup   handing the packet to the transmit DMA - a copy into the
	 *           nocache staging buffer, a CRC, and the driver reprogramming
	 *           the stream.
	 *   flight  send started to the arrival stamp the receive ISR wrote.
	 *           This is the wire in both directions plus everything the far
	 *           side did, and it is where a surprise would live.
	 *   detect  arrival stamp to this loop noticing, which is the price of
	 *           polling the latch instead of being called by it.
	 */
	uint32_t setup_best = UINT32_MAX, flight_best = UINT32_MAX, detect_best = UINT32_MAX;
	uint64_t setup_total = 0, flight_total = 0, detect_total = 0;
	int64_t skew = 0;
	const uint32_t t_start = k_cycle_get_32();

	for (uint32_t k = 1; k <= BURST_PACKETS; k++) {
		memset(&pkt, 0, sizeof(pkt));
		pkt.signal_count = CTRL_LINK_SIGNALS;
		pkt.seq = k;
		pkt.tx_tick = (uint32_t)sys_clock_tick_get();
		for (unsigned int i = 0; i < CTRL_LINK_SIGNALS; i++) {
			pkt.signals[i] = (float)k + (float)i * 0.25f;
		}

		const uint32_t t0 = k_cycle_get_32();

		if (!link_dma_send(&pkt)) {
			tx_refused++;
			consec_drop++;
			if (consec_drop >= MAX_CONSEC_DROP) {
				break;
			}
			continue;
		}

		const uint32_t t1 = k_cycle_get_32();

		if (!wait_for_seq(k, &echo, &rx_cycle, PKT_TIMEOUT_US)) {
			dropped++;
			if (++consec_drop >= MAX_CONSEC_DROP) {
				break;
			}
			continue;
		}

		const uint32_t t2 = k_cycle_get_32();
		const uint32_t rtt = t2 - t0;

		consec_drop = 0;
		answered++;
		rtt_best = MIN(rtt_best, rtt);
		rtt_worst = MAX(rtt_worst, rtt);
		rtt_total += rtt;

		const uint32_t setup = t1 - t0;
		const uint32_t flight = rx_cycle - t1;
		const uint32_t detect = t2 - rx_cycle;

		setup_best = MIN(setup_best, setup);
		flight_best = MIN(flight_best, flight);
		detect_best = MIN(detect_best, detect);
		setup_total += setup;
		flight_total += flight;
		detect_total += detect;

		/* The payload came back through two DMA controllers and two
		 * CRCs. Checking it here is what makes "zero byte loss" a
		 * statement about the bytes rather than about the frame count.
		 */
		for (unsigned int i = 0; i < CTRL_LINK_SIGNALS; i++) {
			if (echo.signals[i] != pkt.signals[i]) {
				payload_bad++;
				break;
			}
		}

		switch (link_latch_step(&latch, &echo, rx_cycle, true, NULL, NULL, &skew)) {
		case LATCH_OVERRUN:
			overrun++;
			break;
		case LATCH_FAULT:
			fault++;
			break;
		default:
			break;
		}
	}

	const uint32_t elapsed = k_cycle_get_32() - t_start;
	const uint32_t hz = sys_clock_hw_cycles_per_sec();

	printk("\nsent        %u\n", answered + dropped + tx_refused);
	printk("answered    %u\n", answered);
	printk("dropped     %u (timeout %u us), tx refused %u\n", dropped,
	       PKT_TIMEOUT_US, tx_refused);
	printk("payload_bad %u\n", payload_bad);
	printk("latch       overrun %u, fault %u, slips %u\n", overrun, fault,
	       latch.total_slips);

	if (answered > 0U) {
		const uint32_t mean = (uint32_t)(rtt_total / answered);
		const uint32_t wire2 = 2U * PKT_WIRE_NS;

		printk("\nrtt_cycles  min=%u mean=%u max=%u spread=%u\n", rtt_best,
		       mean, rtt_worst, rtt_worst - rtt_best);
		printk("rtt_ns      min=%u mean=%u max=%u\n",
		       (uint32_t)((uint64_t)rtt_best * 1000000000ULL / hz),
		       (uint32_t)((uint64_t)mean * 1000000000ULL / hz),
		       (uint32_t)((uint64_t)rtt_worst * 1000000000ULL / hz));
		printk("wire_ns     %u both directions (%u bytes each way)\n", wire2,
		       (unsigned int)CTRL_LINK_PKT_LEN);
		printk("            min / mean, in ns:\n");
		printk("  setup     %u / %u  handing it to the transmit DMA\n",
		       (uint32_t)((uint64_t)setup_best * 1000000000ULL / hz),
		       (uint32_t)(setup_total * 1000000000ULL / answered / hz));
		printk("  flight    %u / %u  wire both ways plus the far side\n",
		       (uint32_t)((uint64_t)flight_best * 1000000000ULL / hz),
		       (uint32_t)(flight_total * 1000000000ULL / answered / hz));
		printk("  detect    %u / %u  arrival stamp to this loop noticing\n",
		       (uint32_t)((uint64_t)detect_best * 1000000000ULL / hz),
		       (uint32_t)(detect_total * 1000000000ULL / answered / hz));

		/* What is left after the wire is software: two DMA arm/complete
		 * paths, two CRCs, the latch on each side, and the responder's
		 * turnaround, which it reports on its own console. Subtract
		 * that too for the initiator-side figure.
		 */
		const uint32_t best_ns = (uint32_t)((uint64_t)rtt_best * 1000000000ULL / hz);

		printk("soft_ns     ~%u round trip after the wire (subtract the\n",
		       best_ns > wire2 ? best_ns - wire2 : 0U);
		printk("            responder turnaround from its own console)\n");
		printk("\nelapsed     %u us for %u packets, %u us each\n",
		       (uint32_t)((uint64_t)elapsed * 1000000ULL / hz), answered,
		       (uint32_t)((uint64_t)elapsed * 1000000ULL / hz / answered));
		printk("skew        %lld cycles accumulated over the burst\n",
		       (long long)skew);
		printk("            (%lld ns; positive means this board's clock ran long)\n",
		       (long long)(skew * 1000000000LL / (int64_t)hz));
		printk("skew_gaps   %u intervals too long to attribute\n", latch.skew_gaps);
	}

	print_link_stats("initiator");
	printk("\ndone\n");
	return 0;
}

#endif /* LINK_RESPONDER */
```

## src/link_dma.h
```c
/*
 * Non-blocking DMA transceiver for the link, stage E3.
 *
 * Both directions are asynchronous: the DMA controller moves the bytes and the
 * CPU is only involved at packet boundaries. Nothing here blocks, spins or
 * locks interrupts, which is the property E3 exists to preserve - see
 * firmware/link/README.md and bead ctrl-lab-b7r.7 for why the E2 polled path
 * could not be carried forward.
 *
 * Threading: link_dma_send() and link_dma_get_latest() are called from the
 * control thread. Everything else runs in the UART callback, which is ISR
 * context. The two meet at a sequence-counted double buffer, so the consumer
 * never blocks the receiver and never reads a half-written packet.
 */

#ifndef CTRL_LINK_DMA_H_
#define CTRL_LINK_DMA_H_

#include <stdbool.h>
#include <stdint.h>
#include <zephyr/device.h>

#include "link_pkt.h"

/* Counters, all free-running. Read them from the control thread; they are
 * written only by the receive callback and only ever increase, so a torn read
 * costs an undercount and nothing else.
 */
struct link_dma_stats {
	uint32_t rx_slots;	/* buffers the DMA filled */
	uint32_t rx_ok;		/* packets that passed magic and CRC */
	uint32_t rx_bad;	/* packets that did not, resync attempted */
	uint32_t resyncs;	/* times the packet boundary moved */
	uint32_t realigns;	/* times the buffer grid was moved to match it */
	uint32_t rx_short;	/* RX_RDY events that were not a whole slot */
	uint32_t rx_errors;	/* UART_RX_STOPPED: overrun, framing, parity */
	uint32_t rx_restarts;	/* times reception had to be re-armed */
	uint32_t tx_done;	/* completed transmits */
	uint32_t tx_rejected;	/* sends refused because one was in flight */
	/* Cost of the receive callback, in cycles. The first call is kept apart
	 * from the rest because it is not the same measurement: it runs with a
	 * cold I-cache and a CRC table nothing has touched yet, and reporting
	 * it as the worst case would describe a startup transient as if it
	 * were the steady state. Both are worth knowing; conflating them is
	 * not.
	 */
	uint32_t rx_first_cycles;
	uint32_t rx_worst_cycles;	/* after the first */
	uint64_t rx_total_cycles;	/* after the first, for the mean */
};

/* Arms reception. Must be called before any packet can arrive; the caller
 * still owns the handshake that decides when the far side starts sending.
 *
 * Returns false, loudly, if the UART is not ready, if the driver rejects the
 * ring, or if the table-driven CRC here disagrees with dcp.c's.
 */
bool link_dma_init(const struct device *uart_dev);

/* Stages a copy of `pkt`, stamps the magic and CRC into it, and hands it to
 * the transmit DMA. Returns immediately.
 *
 * The caller's packet is not modified and need not outlive the call. Returns
 * false if a transmit is still in flight, which at one packet per tick means
 * the far side is not draining or the baud rate is wrong.
 */
bool link_dma_send(const struct ctrl_link_pkt *pkt);

/* Copies the most recently validated packet, and the cycle count at which its
 * last byte landed, out of the latch.
 *
 * Returns false only if nothing has ever been latched. It does NOT report
 * whether the packet is new - the packet's own seq field does that, which is
 * what link_latch_step() uses to tell a fresh sample from a held one.
 */
bool link_dma_get_latest(struct ctrl_link_pkt *out, uint32_t *rx_cycle);

void link_dma_get_stats(struct link_dma_stats *out);

#endif /* CTRL_LINK_DMA_H_ */
```
